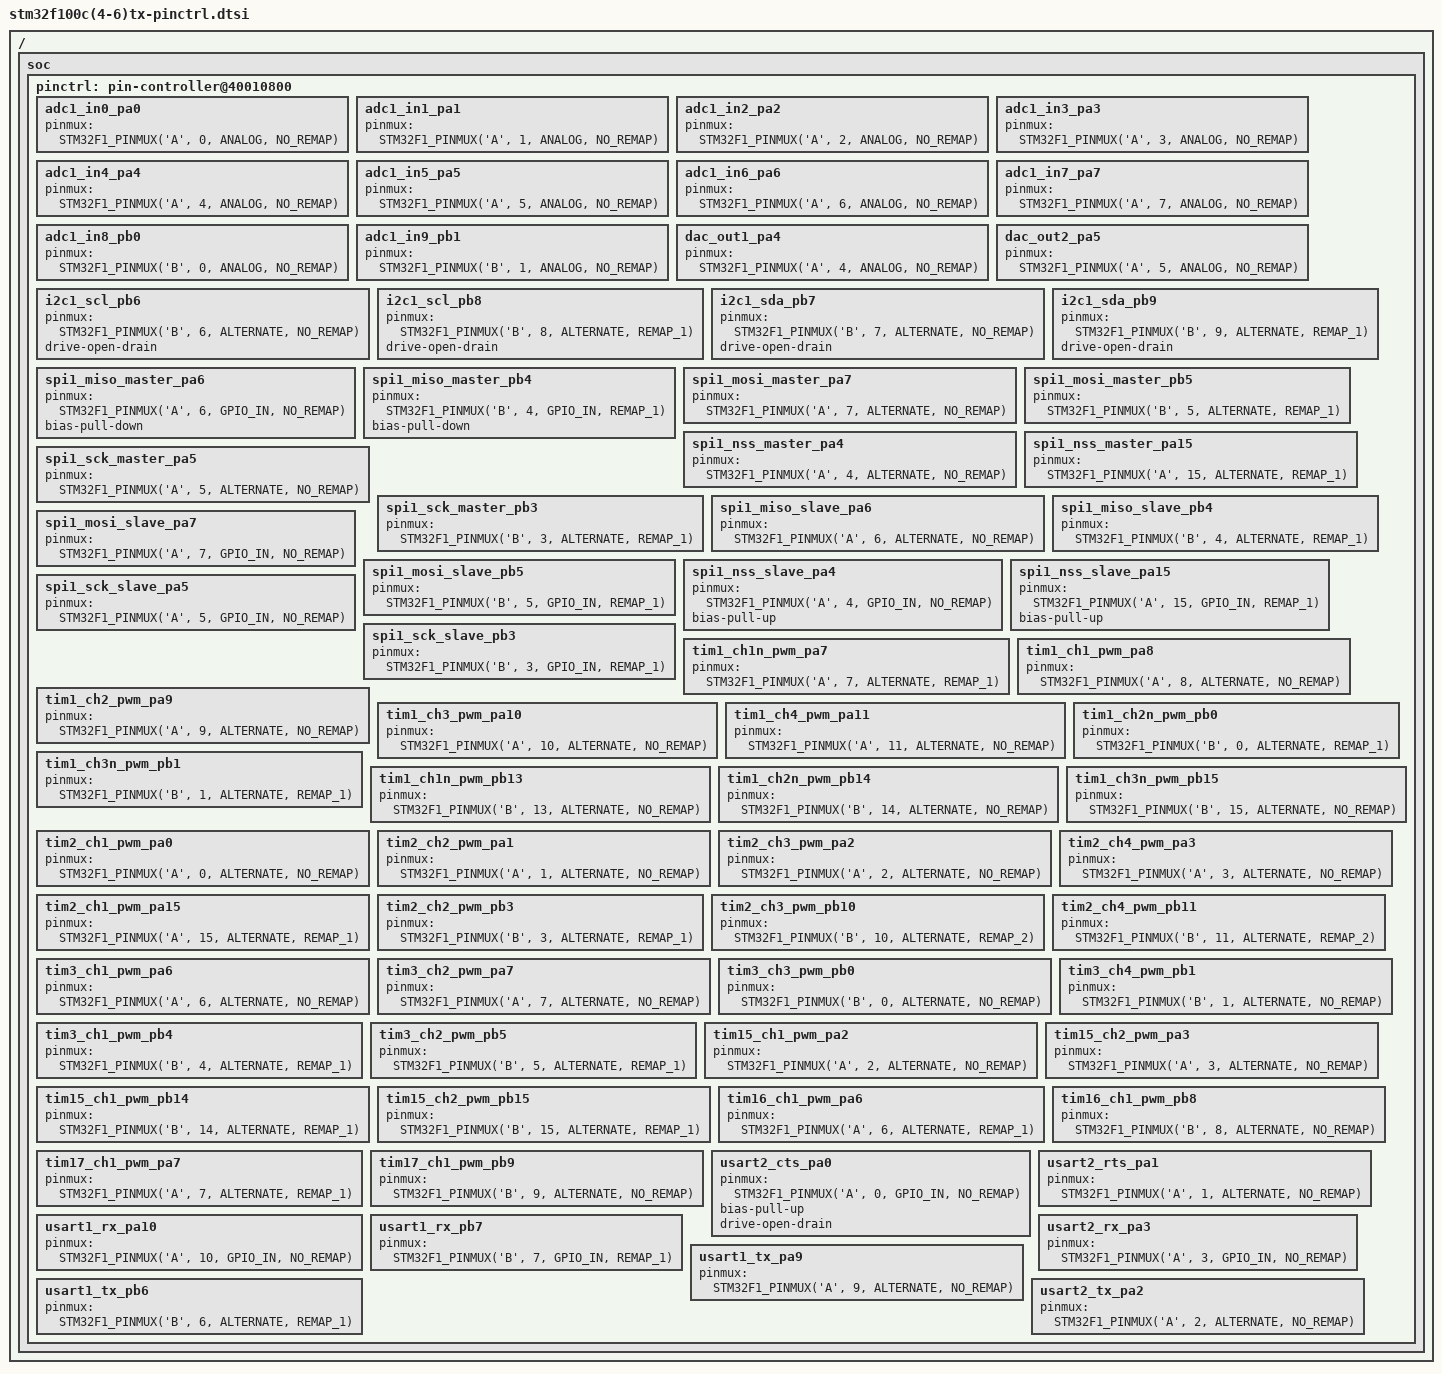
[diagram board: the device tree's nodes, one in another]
/*
 * NOTE: Autogenerated file using genpinctrl.py
 *
 * SPDX-License-Identifier: Apache-2.0
 */

#include <dt-bindings/pinctrl/stm32f1-pinctrl.h>

/ {
	soc {
		pinctrl: pin-controller@40010800 {

			/* ADC_IN */

			adc1_in0_pa0: adc1_in0_pa0 {
				pinmux = <STM32F1_PINMUX('A', 0, ANALOG, NO_REMAP)>;
			};

			adc1_in1_pa1: adc1_in1_pa1 {
				pinmux = <STM32F1_PINMUX('A', 1, ANALOG, NO_REMAP)>;
			};

			adc1_in2_pa2: adc1_in2_pa2 {
				pinmux = <STM32F1_PINMUX('A', 2, ANALOG, NO_REMAP)>;
			};

			adc1_in3_pa3: adc1_in3_pa3 {
				pinmux = <STM32F1_PINMUX('A', 3, ANALOG, NO_REMAP)>;
			};

			adc1_in4_pa4: adc1_in4_pa4 {
				pinmux = <STM32F1_PINMUX('A', 4, ANALOG, NO_REMAP)>;
			};

			adc1_in5_pa5: adc1_in5_pa5 {
				pinmux = <STM32F1_PINMUX('A', 5, ANALOG, NO_REMAP)>;
			};

			adc1_in6_pa6: adc1_in6_pa6 {
				pinmux = <STM32F1_PINMUX('A', 6, ANALOG, NO_REMAP)>;
			};

			adc1_in7_pa7: adc1_in7_pa7 {
				pinmux = <STM32F1_PINMUX('A', 7, ANALOG, NO_REMAP)>;
			};

			adc1_in8_pb0: adc1_in8_pb0 {
				pinmux = <STM32F1_PINMUX('B', 0, ANALOG, NO_REMAP)>;
			};

			adc1_in9_pb1: adc1_in9_pb1 {
				pinmux = <STM32F1_PINMUX('B', 1, ANALOG, NO_REMAP)>;
			};

			/* DAC_OUT */

			dac_out1_pa4: dac_out1_pa4 {
				pinmux = <STM32F1_PINMUX('A', 4, ANALOG, NO_REMAP)>;
			};

			dac_out2_pa5: dac_out2_pa5 {
				pinmux = <STM32F1_PINMUX('A', 5, ANALOG, NO_REMAP)>;
			};

			/* I2C_SCL */

			i2c1_scl_pb6: i2c1_scl_pb6 {
				pinmux = <STM32F1_PINMUX('B', 6, ALTERNATE, NO_REMAP)>;
				drive-open-drain;
			};

			i2c1_scl_pb8: i2c1_scl_pb8 {
				pinmux = <STM32F1_PINMUX('B', 8, ALTERNATE, REMAP_1)>;
				drive-open-drain;
			};

			/* I2C_SDA */

			i2c1_sda_pb7: i2c1_sda_pb7 {
				pinmux = <STM32F1_PINMUX('B', 7, ALTERNATE, NO_REMAP)>;
				drive-open-drain;
			};

			i2c1_sda_pb9: i2c1_sda_pb9 {
				pinmux = <STM32F1_PINMUX('B', 9, ALTERNATE, REMAP_1)>;
				drive-open-drain;
			};

			/* SPI_MASTER_MISO */

			spi1_miso_master_pa6: spi1_miso_master_pa6 {
				pinmux = <STM32F1_PINMUX('A', 6, GPIO_IN, NO_REMAP)>;
				bias-pull-down;
			};

			spi1_miso_master_pb4: spi1_miso_master_pb4 {
				pinmux = <STM32F1_PINMUX('B', 4, GPIO_IN, REMAP_1)>;
				bias-pull-down;
			};

			/* SPI_MASTER_MOSI */

			spi1_mosi_master_pa7: spi1_mosi_master_pa7 {
				pinmux = <STM32F1_PINMUX('A', 7, ALTERNATE, NO_REMAP)>;
			};

			spi1_mosi_master_pb5: spi1_mosi_master_pb5 {
				pinmux = <STM32F1_PINMUX('B', 5, ALTERNATE, REMAP_1)>;
			};

			/* SPI_MASTER_NSS */

			spi1_nss_master_pa4: spi1_nss_master_pa4 {
				pinmux = <STM32F1_PINMUX('A', 4, ALTERNATE, NO_REMAP)>;
			};

			spi1_nss_master_pa15: spi1_nss_master_pa15 {
				pinmux = <STM32F1_PINMUX('A', 15, ALTERNATE, REMAP_1)>;
			};

			/* SPI_MASTER_SCK */

			spi1_sck_master_pa5: spi1_sck_master_pa5 {
				pinmux = <STM32F1_PINMUX('A', 5, ALTERNATE, NO_REMAP)>;
			};

			spi1_sck_master_pb3: spi1_sck_master_pb3 {
				pinmux = <STM32F1_PINMUX('B', 3, ALTERNATE, REMAP_1)>;
			};

			/* SPI_SLAVE_MISO */

			spi1_miso_slave_pa6: spi1_miso_slave_pa6 {
				pinmux = <STM32F1_PINMUX('A', 6, ALTERNATE, NO_REMAP)>;
			};

			spi1_miso_slave_pb4: spi1_miso_slave_pb4 {
				pinmux = <STM32F1_PINMUX('B', 4, ALTERNATE, REMAP_1)>;
			};

			/* SPI_SLAVE_MOSI */

			spi1_mosi_slave_pa7: spi1_mosi_slave_pa7 {
				pinmux = <STM32F1_PINMUX('A', 7, GPIO_IN, NO_REMAP)>;
			};

			spi1_mosi_slave_pb5: spi1_mosi_slave_pb5 {
				pinmux = <STM32F1_PINMUX('B', 5, GPIO_IN, REMAP_1)>;
			};

			/* SPI_SLAVE_NSS */

			spi1_nss_slave_pa4: spi1_nss_slave_pa4 {
				pinmux = <STM32F1_PINMUX('A', 4, GPIO_IN, NO_REMAP)>;
				bias-pull-up;
			};

			spi1_nss_slave_pa15: spi1_nss_slave_pa15 {
				pinmux = <STM32F1_PINMUX('A', 15, GPIO_IN, REMAP_1)>;
				bias-pull-up;
			};

			/* SPI_SLAVE_SCK */

			spi1_sck_slave_pa5: spi1_sck_slave_pa5 {
				pinmux = <STM32F1_PINMUX('A', 5, GPIO_IN, NO_REMAP)>;
			};

			spi1_sck_slave_pb3: spi1_sck_slave_pb3 {
				pinmux = <STM32F1_PINMUX('B', 3, GPIO_IN, REMAP_1)>;
			};

			/* TIM_CH_PWM / TIM_CHN_PWM */

			tim1_ch1n_pwm_pa7: tim1_ch1n_pwm_pa7 {
				pinmux = <STM32F1_PINMUX('A', 7, ALTERNATE, REMAP_1)>;
			};

			tim1_ch1_pwm_pa8: tim1_ch1_pwm_pa8 {
				pinmux = <STM32F1_PINMUX('A', 8, ALTERNATE, NO_REMAP)>;
			};

			tim1_ch2_pwm_pa9: tim1_ch2_pwm_pa9 {
				pinmux = <STM32F1_PINMUX('A', 9, ALTERNATE, NO_REMAP)>;
			};

			tim1_ch3_pwm_pa10: tim1_ch3_pwm_pa10 {
				pinmux = <STM32F1_PINMUX('A', 10, ALTERNATE, NO_REMAP)>;
			};

			tim1_ch4_pwm_pa11: tim1_ch4_pwm_pa11 {
				pinmux = <STM32F1_PINMUX('A', 11, ALTERNATE, NO_REMAP)>;
			};

			tim1_ch2n_pwm_pb0: tim1_ch2n_pwm_pb0 {
				pinmux = <STM32F1_PINMUX('B', 0, ALTERNATE, REMAP_1)>;
			};

			tim1_ch3n_pwm_pb1: tim1_ch3n_pwm_pb1 {
				pinmux = <STM32F1_PINMUX('B', 1, ALTERNATE, REMAP_1)>;
			};

			tim1_ch1n_pwm_pb13: tim1_ch1n_pwm_pb13 {
				pinmux = <STM32F1_PINMUX('B', 13, ALTERNATE, NO_REMAP)>;
			};

			tim1_ch2n_pwm_pb14: tim1_ch2n_pwm_pb14 {
				pinmux = <STM32F1_PINMUX('B', 14, ALTERNATE, NO_REMAP)>;
			};

			tim1_ch3n_pwm_pb15: tim1_ch3n_pwm_pb15 {
				pinmux = <STM32F1_PINMUX('B', 15, ALTERNATE, NO_REMAP)>;
			};

			tim2_ch1_pwm_pa0: tim2_ch1_pwm_pa0 {
				pinmux = <STM32F1_PINMUX('A', 0, ALTERNATE, NO_REMAP)>;
			};

			tim2_ch2_pwm_pa1: tim2_ch2_pwm_pa1 {
				pinmux = <STM32F1_PINMUX('A', 1, ALTERNATE, NO_REMAP)>;
			};

			tim2_ch3_pwm_pa2: tim2_ch3_pwm_pa2 {
				pinmux = <STM32F1_PINMUX('A', 2, ALTERNATE, NO_REMAP)>;
			};

			tim2_ch4_pwm_pa3: tim2_ch4_pwm_pa3 {
				pinmux = <STM32F1_PINMUX('A', 3, ALTERNATE, NO_REMAP)>;
			};

			tim2_ch1_pwm_pa15: tim2_ch1_pwm_pa15 {
				pinmux = <STM32F1_PINMUX('A', 15, ALTERNATE, REMAP_1)>;
			};

			tim2_ch2_pwm_pb3: tim2_ch2_pwm_pb3 {
				pinmux = <STM32F1_PINMUX('B', 3, ALTERNATE, REMAP_1)>;
			};

			tim2_ch3_pwm_pb10: tim2_ch3_pwm_pb10 {
				pinmux = <STM32F1_PINMUX('B', 10, ALTERNATE, REMAP_2)>;
			};

			tim2_ch4_pwm_pb11: tim2_ch4_pwm_pb11 {
				pinmux = <STM32F1_PINMUX('B', 11, ALTERNATE, REMAP_2)>;
			};

			tim3_ch1_pwm_pa6: tim3_ch1_pwm_pa6 {
				pinmux = <STM32F1_PINMUX('A', 6, ALTERNATE, NO_REMAP)>;
			};

			tim3_ch2_pwm_pa7: tim3_ch2_pwm_pa7 {
				pinmux = <STM32F1_PINMUX('A', 7, ALTERNATE, NO_REMAP)>;
			};

			tim3_ch3_pwm_pb0: tim3_ch3_pwm_pb0 {
				pinmux = <STM32F1_PINMUX('B', 0, ALTERNATE, NO_REMAP)>;
			};

			tim3_ch4_pwm_pb1: tim3_ch4_pwm_pb1 {
				pinmux = <STM32F1_PINMUX('B', 1, ALTERNATE, NO_REMAP)>;
			};

			tim3_ch1_pwm_pb4: tim3_ch1_pwm_pb4 {
				pinmux = <STM32F1_PINMUX('B', 4, ALTERNATE, REMAP_1)>;
			};

			tim3_ch2_pwm_pb5: tim3_ch2_pwm_pb5 {
				pinmux = <STM32F1_PINMUX('B', 5, ALTERNATE, REMAP_1)>;
			};

			tim15_ch1_pwm_pa2: tim15_ch1_pwm_pa2 {
				pinmux = <STM32F1_PINMUX('A', 2, ALTERNATE, NO_REMAP)>;
			};

			tim15_ch2_pwm_pa3: tim15_ch2_pwm_pa3 {
				pinmux = <STM32F1_PINMUX('A', 3, ALTERNATE, NO_REMAP)>;
			};

			tim15_ch1_pwm_pb14: tim15_ch1_pwm_pb14 {
				pinmux = <STM32F1_PINMUX('B', 14, ALTERNATE, REMAP_1)>;
			};

			tim15_ch2_pwm_pb15: tim15_ch2_pwm_pb15 {
				pinmux = <STM32F1_PINMUX('B', 15, ALTERNATE, REMAP_1)>;
			};

			tim16_ch1_pwm_pa6: tim16_ch1_pwm_pa6 {
				pinmux = <STM32F1_PINMUX('A', 6, ALTERNATE, REMAP_1)>;
			};

			tim16_ch1_pwm_pb8: tim16_ch1_pwm_pb8 {
				pinmux = <STM32F1_PINMUX('B', 8, ALTERNATE, NO_REMAP)>;
			};

			tim17_ch1_pwm_pa7: tim17_ch1_pwm_pa7 {
				pinmux = <STM32F1_PINMUX('A', 7, ALTERNATE, REMAP_1)>;
			};

			tim17_ch1_pwm_pb9: tim17_ch1_pwm_pb9 {
				pinmux = <STM32F1_PINMUX('B', 9, ALTERNATE, NO_REMAP)>;
			};

			/* UART_CTS / USART_CTS */

			usart2_cts_pa0: usart2_cts_pa0 {
				pinmux = <STM32F1_PINMUX('A', 0, GPIO_IN, NO_REMAP)>;
				bias-pull-up;
				drive-open-drain;
			};

			/* UART_RTS / USART_RTS */

			usart2_rts_pa1: usart2_rts_pa1 {
				pinmux = <STM32F1_PINMUX('A', 1, ALTERNATE, NO_REMAP)>;
			};

			/* UART_RX / USART_RX */

			usart1_rx_pa10: usart1_rx_pa10 {
				pinmux = <STM32F1_PINMUX('A', 10, GPIO_IN, NO_REMAP)>;
			};

			usart1_rx_pb7: usart1_rx_pb7 {
				pinmux = <STM32F1_PINMUX('B', 7, GPIO_IN, REMAP_1)>;
			};

			usart2_rx_pa3: usart2_rx_pa3 {
				pinmux = <STM32F1_PINMUX('A', 3, GPIO_IN, NO_REMAP)>;
			};

			/* UART_TX / USART_TX */

			usart1_tx_pa9: usart1_tx_pa9 {
				pinmux = <STM32F1_PINMUX('A', 9, ALTERNATE, NO_REMAP)>;
			};

			usart1_tx_pb6: usart1_tx_pb6 {
				pinmux = <STM32F1_PINMUX('B', 6, ALTERNATE, REMAP_1)>;
			};

			usart2_tx_pa2: usart2_tx_pa2 {
				pinmux = <STM32F1_PINMUX('A', 2, ALTERNATE, NO_REMAP)>;
			};

		};
	};
};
